# ESP32-P4 register map
Vendor: ESPRESSIF SYSTEMS (SHANGHAI) CO., LTD.; Series: ESP32 P-Series; File version: 3
CPU: RV32IMAFC r0p0, little endian, no MPU, FPU, 0 interrupt priority bits
Address unit: 32 bits
Registers are 32-bit, read-write, reset 0x0 unless marked. A register's access mark holds for its fields unless they carry their own. Offsets are from the block's base; [hi:lo] are bit positions; lines under a group give offsets from that group; {n}, {i} and the like mark numbered series; <NAME> marks a mode.

## H264 — H264 Encoder (Core)
Base 0x50084000
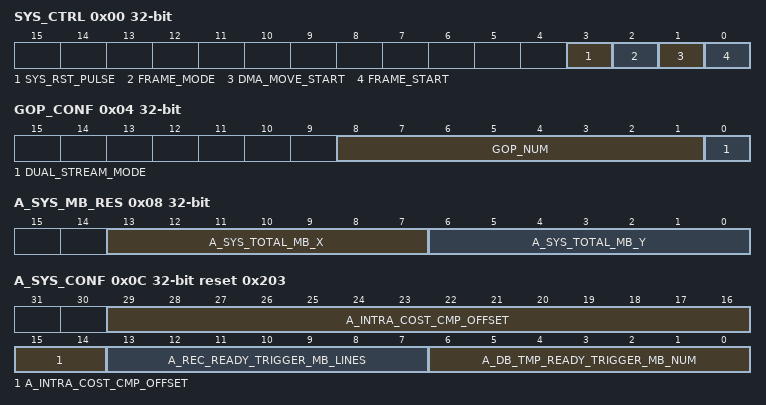
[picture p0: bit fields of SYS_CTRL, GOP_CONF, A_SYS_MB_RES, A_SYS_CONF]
0x00 SYS_CTRL access per field — H264 system level control register.
  [3] SYS_RST_PULSE wo — Configures whether or not to reset H264 ip.\\0: Invalid. No effect\\1: Reset H264 ip
  [2] FRAME_MODE rw — Configures H264 running mode. When field H264_DUAL_STREAM_MODE is set to 1, this field must be set to 1 too.\\0: GOP mode. Before every GOP first frame start, need reconfig reference frame DMA\\1: Frame mode. Before every frame start, need reconfig reference frame DMA
  [1] DMA_MOVE_START wo — Configures whether or not to start moving reference data from external mem.\\0: Invalid. No effect\\1: H264 start moving two MB lines of reference frame from external mem to internal mem
  [0] FRAME_START wo — Configures whether or not to start encoding one frame.\\0: Invalid. No effect\\1: Start encoding one frame
0x04 GOP_CONF — GOP related configuration register.
  [8:1] GOP_NUM — Configures the frame number of one GOP.\\0: The frame number of one GOP is infinite\\Others: Actual frame number of one GOP
  [0] DUAL_STREAM_MODE — Configures whether or not to enable dual stream mode. When this field is set to 1, H264_FRAME_MODE field must be set to 1 too.\\0: Normal mode\\1: Dual stream mode
0x08 A_SYS_MB_RES — Video A horizontal and vertical MB resolution register.
  [13:7] A_SYS_TOTAL_MB_X — Configures video A horizontal MB resolution.
  [6:0] A_SYS_TOTAL_MB_Y — Configures video A vertical MB resolution.
0x0C A_SYS_CONF reset 0x203 — Video A system level configuration register.
  [29:14] A_INTRA_COST_CMP_OFFSET — Configures video A intra cost offset when I MB compared with P MB.
  [13:7] A_REC_READY_TRIGGER_MB_LINES — Configures when to trigger video A H264_REC_READY_INT. When the MB line number of generated reconstruct pixel is greater than this filed, trigger H264_REC_READY_INT. Min is 4.
  [6:0] A_DB_TMP_READY_TRIGGER_MB_NUM — Configures when to trigger video A H264_DB_TMP_READY_INT. When the (MB number of written db temp+1) is greater than this filed in first MB line, trigger H264_DB_TMP_READY_INT. Min is 3.
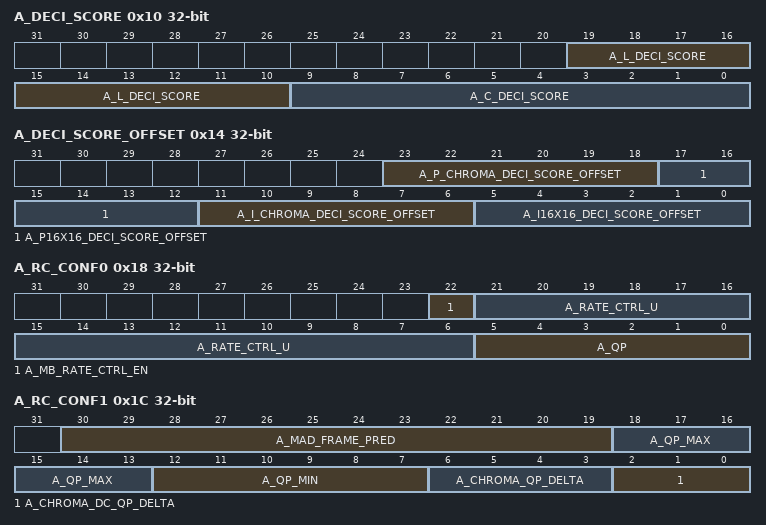
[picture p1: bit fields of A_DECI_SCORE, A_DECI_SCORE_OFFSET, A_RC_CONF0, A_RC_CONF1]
0x10 A_DECI_SCORE — Video A luma and chroma MB decimate score Register.
  [19:10] A_L_DECI_SCORE — Configures video A luma MB decimate score. When luma score is smaller than it, luma decimate will be enable.
  [9:0] A_C_DECI_SCORE — Configures video A chroma MB decimate score. When chroma score is smaller than it, chroma decimate will be enable.
0x14 A_DECI_SCORE_OFFSET — Video A luma and chroma MB decimate score offset Register.
  [23:18] A_P_CHROMA_DECI_SCORE_OFFSET — Configures video A p chroma MB decimate score offset. This offset will be added to p chroma MB score.
  [17:12] A_P16X16_DECI_SCORE_OFFSET — Configures video A p16x16 MB decimate score offset. This offset will be added to p16x16 MB score.
  [11:6] A_I_CHROMA_DECI_SCORE_OFFSET — Configures video A I chroma MB decimate score offset. This offset will be added to I chroma MB score.
  [5:0] A_I16X16_DECI_SCORE_OFFSET — Configures video A i16x16 MB decimate score offset. This offset will be added to i16x16 MB score.
0x18 A_RC_CONF0 — Video A rate control configuration register0.
  [22] A_MB_RATE_CTRL_EN — Configures video A whether or not to open macro block rate ctrl.\\1:Open the macro block rate ctrl\\1:Close the macro block rate ctrl.
  [21:6] A_RATE_CTRL_U — Configures video A parameter U value. U = int((float) u << 8).
  [5:0] A_QP — Configures video A frame level initial luma QP value.
0x1C A_RC_CONF1 — Video A rate control configuration register1.
  [30:19] A_MAD_FRAME_PRED — Configures vdieo A frame level predicted MB MAD value.
  [18:13] A_QP_MAX — Configures video A allowed luma QP max value.
  [12:7] A_QP_MIN — Configures video A allowed luma QP min value.
  [6:3] A_CHROMA_QP_DELTA — Configures video A chroma QP offset based on luma QP. Chroma QP(before map) = Luma QP + reg_chroma_qp_delta.
  [2:0] A_CHROMA_DC_QP_DELTA — Configures video A chroma DC QP offset based on Chroma QP. Chroma DC QP = Chroma QP(after map) + reg_chroma_dc_qp_delta.
0x20 A_DB_BYPASS — Video A Deblocking bypass register
  [0] A_BYPASS_DB_FILTER — Configures whether or not to bypass video A deblcoking filter. \\0: Open the deblock filter\\1: Close the deblock filter
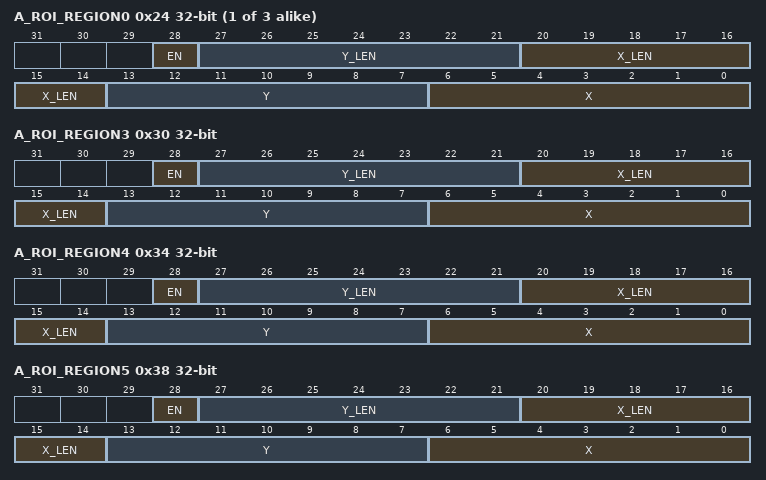
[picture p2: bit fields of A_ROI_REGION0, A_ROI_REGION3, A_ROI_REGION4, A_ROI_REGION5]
{0x24+4i} A_ROI_REGION{i} (i=0..2) — Video A H264 ROI region{i} range configure register.
  [28] EN — Configures whether or not to open Video A ROI of region {i} .\\0:Close ROI\\1:Open ROI.
  [27:21] Y_LEN — Configures the number of macroblocks in vertical direction of the region {i} in Video A.
  [20:14] X_LEN — Configures the number of macroblocks in horizontal direction of the region {i} in Video A.
  [13:7] Y — Configures the vertical start macroblocks of region {i} in Video A.
  [6:0] X — Configures the horizontal start macroblocks of region {i} in Video A.
0x30 A_ROI_REGION3 — Video A H264 ROI region3 range configure register.
  [28] EN — Configures whether or not to open Video A ROI of region 3 .\\0:Close ROI\\1:Open ROI.
  [27:21] Y_LEN — Configures the number of macroblocks in vertical direction of the region 3 in video A.
  [20:14] X_LEN — Configures the number of macroblocks in horizontal direction of the region 3 in video A.
  [13:7] Y — Configures the vertical start macroblocks of region 3 in Video A.
  [6:0] X — Configures the horizontal start macroblocks of region 3 in Video A.
0x34 A_ROI_REGION4 — Video A H264 ROI region4 range configure register.
  [28] EN — Configures whether or not to open Video A ROI of region 4 .\\0:Close ROI\\1:Open ROI.
  [27:21] Y_LEN — Configures the number of macroblocks in vertical direction of the region 4 in video A.
  [20:14] X_LEN — Configures the number of macroblocks in horizontal direction of the region 4 in video A.
  [13:7] Y — Configures the vertical start macroblocks of region 4 in Video A.
  [6:0] X — Configures the horizontal start macroblocks of region 4 in Video A.
0x38 A_ROI_REGION5 — Video A H264 ROI region5 range configure register.
  [28] EN — Configures whether or not to open Video A ROI of region 5 .\\0:Close ROI\\1:Open ROI.
  [27:21] Y_LEN — Configures the number of macroblocks in vertical direction of the region 5 in video A.
  [20:14] X_LEN — Configures the number of macroblocks in horizontal direction of the region 5 video A.
  [13:7] Y — Configures the vertical start macroblocks of region 5 video A.
  [6:0] X — Configures the horizontial start macroblocks of region 5 video A.
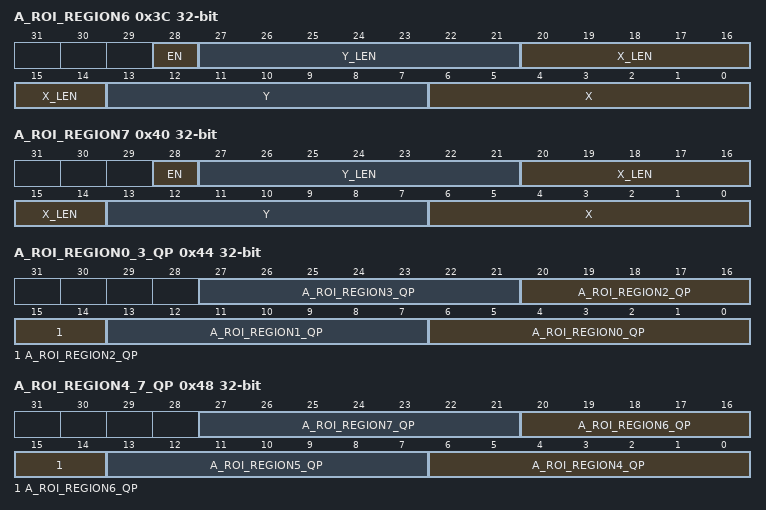
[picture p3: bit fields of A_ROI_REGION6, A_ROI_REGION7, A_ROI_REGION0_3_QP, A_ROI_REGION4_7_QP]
0x3C A_ROI_REGION6 — Video A H264 ROI region6 range configure register.
  [28] EN — Configures whether or not to open Video A ROI of region 6 .\\0:Close ROI\\1:Open ROI.
  [27:21] Y_LEN — Configures the number of macroblocks in vertical direction of the region 6 in video A.
  [20:14] X_LEN — Configures the number of macroblocks in horizontal direction of the region 6 in video A.
  [13:7] Y — Configures the vertical start macroblocks of region 6 in video A.
  [6:0] X — Configures the horizontial start macroblocks of region 6 video A.
0x40 A_ROI_REGION7 — Video A H264 ROI region7 range configure register.
  [28] EN — Configures whether or not to open Video A ROI of region 7 .\\0:Close ROI\\1:Open ROI.
  [27:21] Y_LEN — Configures the number of macroblocks in vertical direction of the region 7 in video A.
  [20:14] X_LEN — Configures the number of macroblocks in horizontal direction of the region 7 in video A.
  [13:7] Y — Configures the vertical start macroblocks of region 7 in video A.
  [6:0] X — Configures the horizontal start macroblocks of region 7 in video A.
0x44 A_ROI_REGION0_3_QP — Video A H264 ROI region0, region1,region2,region3 QP register.
  [7n+6:7n] A_ROI_REGION{n}_QP (n=0..3) — Configure H264 ROI region{n} qp in video A,fixed qp or delta qp.
0x48 A_ROI_REGION4_7_QP — Video A H264 ROI region4, region5,region6,region7 QP register.
  [7n-22:7n-28] A_ROI_REGION{n}_QP (n=4..7) — Configure H264 ROI region{n} qp in video A,fixed qp or delta qp.
0x4C A_NO_ROI_REGION_QP_OFFSET — Video A H264 no roi region QP register.
  [6:0] A_NO_ROI_REGION_QP — Configure H264 no region qp in video A, delta qp.
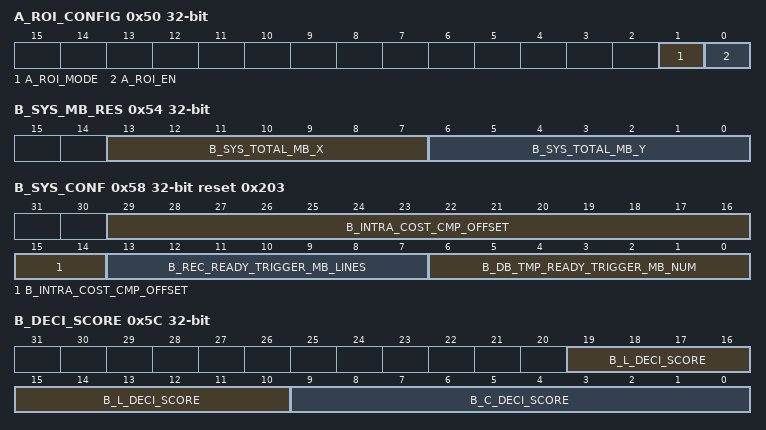
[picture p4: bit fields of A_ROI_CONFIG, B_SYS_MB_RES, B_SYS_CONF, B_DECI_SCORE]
0x50 A_ROI_CONFIG — Video A H264 ROI configure register.
  [1] A_ROI_MODE — Configure the mode of ROI in video A.\\0:fixed qp\\1:delta qp.
  [0] A_ROI_EN — Configure whether or not to enable ROI in video A.\\0:not enable ROI\\1:enable ROI.
0x54 B_SYS_MB_RES — Video B horizontal and vertical MB resolution register.
  [13:7] B_SYS_TOTAL_MB_X — Configures video B horizontal MB resolution.
  [6:0] B_SYS_TOTAL_MB_Y — Configures video B vertical MB resolution.
0x58 B_SYS_CONF reset 0x203 — Video B system level configuration register.
  [29:14] B_INTRA_COST_CMP_OFFSET — Configures video B intra cost offset when I MB compared with P MB.
  [13:7] B_REC_READY_TRIGGER_MB_LINES — Configures when to trigger video B H264_REC_READY_INT. When the MB line number of generated reconstruct pixel is greater than this filed, trigger H264_REC_READY_INT. Min is 4.
  [6:0] B_DB_TMP_READY_TRIGGER_MB_NUM — Configures when to trigger video B H264_DB_TMP_READY_INT. When the (MB number of written db temp+1) is greater than this filed in first MB line, trigger H264_DB_TMP_READY_INT. Min is 3.
0x5C B_DECI_SCORE — Video B luma and chroma MB decimate score Register.
  [19:10] B_L_DECI_SCORE — Configures video B luma MB decimate score. When luma score is smaller than it, luma decimate will be enable.
  [9:0] B_C_DECI_SCORE — Configures video B chroma MB decimate score. When chroma score is smaller than it, chroma decimate will be enable.
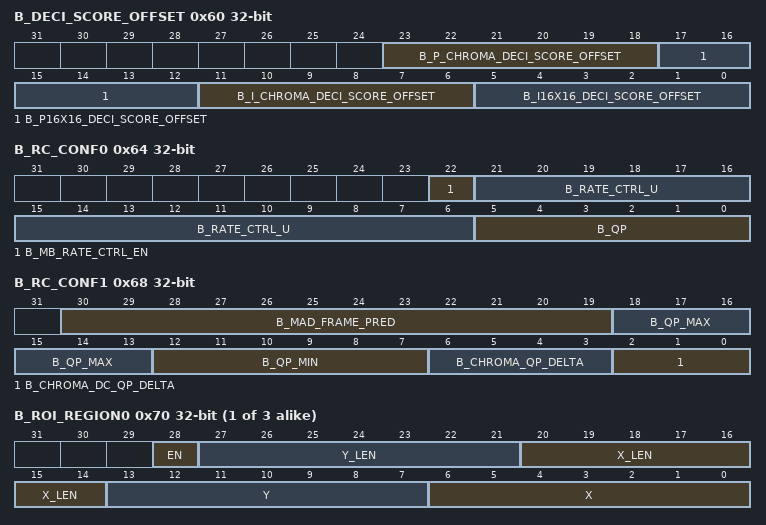
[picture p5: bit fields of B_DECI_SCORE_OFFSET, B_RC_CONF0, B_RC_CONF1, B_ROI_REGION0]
0x60 B_DECI_SCORE_OFFSET — Video B luma and chroma MB decimate score offset Register.
  [23:18] B_P_CHROMA_DECI_SCORE_OFFSET — Configures video B p chroma MB decimate score offset. This offset will be added to p chroma MB score.
  [17:12] B_P16X16_DECI_SCORE_OFFSET — Configures video B p16x16 MB decimate score offset. This offset will be added to p16x16 MB score.
  [11:6] B_I_CHROMA_DECI_SCORE_OFFSET — Configures video B I chroma MB decimate score offset. This offset will be added to I chroma MB score.
  [5:0] B_I16X16_DECI_SCORE_OFFSET — Configures video B i16x16 MB decimate score offset. This offset will be added to i16x16 MB score.
0x64 B_RC_CONF0 — Video B rate control configuration register0.
  [22] B_MB_RATE_CTRL_EN — Configures video A whether or not to open macro block rate ctrl.\\1:Open the macro block rate ctrl\\1:Close the macro block rate ctrl.
  [21:6] B_RATE_CTRL_U — Configures video B parameter U value. U = int((float) u << 8).
  [5:0] B_QP — Configures video B frame level initial luma QP value.
0x68 B_RC_CONF1 — Video B rate control configuration register1.
  [30:19] B_MAD_FRAME_PRED — Configures vdieo B frame level predicted MB MAD value.
  [18:13] B_QP_MAX — Configures video B allowed luma QP max value.
  [12:7] B_QP_MIN — Configures video B allowed luma QP min value.
  [6:3] B_CHROMA_QP_DELTA — Configures video B chroma QP offset based on luma QP. Chroma QP(before map) = Luma QP + reg_chroma_qp_delta.
  [2:0] B_CHROMA_DC_QP_DELTA — Configures video B chroma DC QP offset based on Chroma QP. Chroma DC QP = Chroma QP(after map) + reg_chroma_dc_qp_delta.
0x6C B_DB_BYPASS — Video B Deblocking bypass register
  [0] B_BYPASS_DB_FILTER — Configures whether or not to bypass video B deblcoking filter. \\0: Open the deblock filter\\1: Close the deblock filter
{0x70+4i} B_ROI_REGION{i} (i=0..2) — Video B H264 ROI region{i} range configure register.
  [28] EN — Configures whether or not to open Video B ROI of region {i} .\\0:Close ROI\\1:Open ROI.
  [27:21] Y_LEN — Configures the number of macroblocks in vertical direction of the region {i} in Video B.
  [20:14] X_LEN — Configures the number of macroblocks in horizontal direction of the region {i} in Video B.
  [13:7] Y — Configures the vertical start macroblocks of region {i} in Video B.
  [6:0] X — Configures the horizontal start macroblocks of region {i} in Video B.
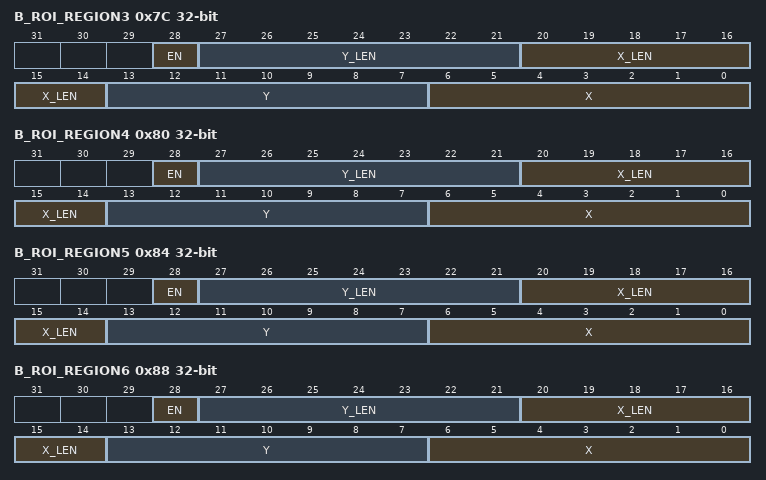
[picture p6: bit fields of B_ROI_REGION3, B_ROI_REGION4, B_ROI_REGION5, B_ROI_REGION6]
0x7C B_ROI_REGION3 — Video B H264 ROI region3 range configure register.
  [28] EN — Configures whether or not to open Video B ROI of region 3 .\\0:Close ROI\\1:Open ROI.
  [27:21] Y_LEN — Configures the number of macroblocks in vertical direction of the region 3 in video B.
  [20:14] X_LEN — Configures the number of macroblocks in horizontal direction of the region 3 in video B.
  [13:7] Y — Configures the vertical start macroblocks of region 3 in Video B.
  [6:0] X — Configures the horizontal start macroblocks of region 3 in Video B.
0x80 B_ROI_REGION4 — Video B H264 ROI region4 range configure register.
  [28] EN — Configures whether or not to open Video B ROI of region 4 .\\0:Close ROI\\1:Open ROI.
  [27:21] Y_LEN — Configures the number of macroblocks in vertical direction of the region 4 in video B.
  [20:14] X_LEN — Configures the number of macroblocks in horizontal direction of the region 4 in video B.
  [13:7] Y — Configures the vertical start macroblocks of region 4 in Video B.
  [6:0] X — Configures the horizontal start macroblocks of region 4 in Video B.
0x84 B_ROI_REGION5 — Video B H264 ROI region5 range configure register.
  [28] EN — Configures whether or not to open Video B ROI of region 5 .\\0:Close ROI\\1:Open ROI.
  [27:21] Y_LEN — Configures the number of macroblocks in vertical direction of the region 5 in video B.
  [20:14] X_LEN — Configures the number of macroblocks in horizontal direction of the region 5 video B.
  [13:7] Y — Configures the vertical start macroblocks of region 5 video B.
  [6:0] X — Configures the horizontial start macroblocks of region 5 video B.
0x88 B_ROI_REGION6 — Video B H264 ROI region6 range configure register.
  [28] EN — Configures whether or not to open Video B ROI of region 6 .\\0:Close ROI\\1:Open ROI.
  [27:21] Y_LEN — Configures the number of macroblocks in vertical direction of the region 6 in video B.
  [20:14] X_LEN — Configures the number of macroblocks in horizontal direction of the region 6 in video B.
  [13:7] Y — Configures the vertical start macroblocks of region 6 in video B.
  [6:0] X — Configures the horizontial start macroblocks of region 6 video B.
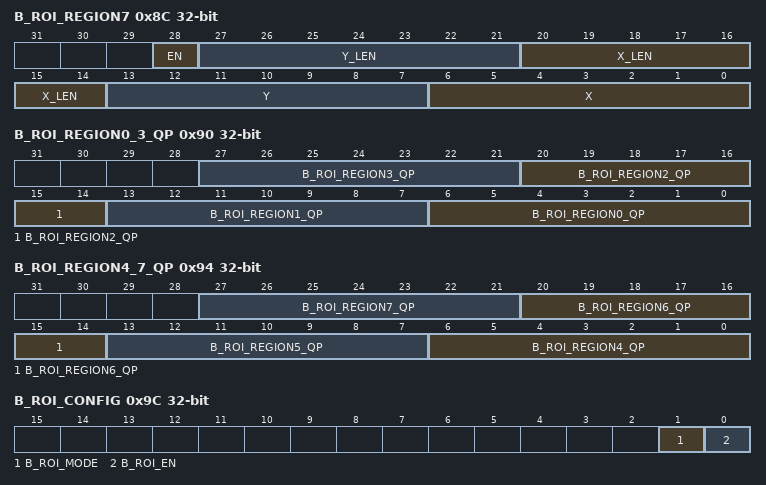
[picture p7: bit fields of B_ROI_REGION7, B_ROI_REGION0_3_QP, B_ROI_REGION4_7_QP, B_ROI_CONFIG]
0x8C B_ROI_REGION7 — Video B H264 ROI region7 range configure register.
  [28] EN — Configures whether or not to open Video B ROI of region 7 .\\0:Close ROI\\1:Open ROI.
  [27:21] Y_LEN — Configures the number of macroblocks in vertical direction of the region 7 in video B.
  [20:14] X_LEN — Configures the number of macroblocks in horizontal direction of the region 7 in video B.
  [13:7] Y — Configures the vertical start macroblocks of region 7 in video B.
  [6:0] X — Configures the horizontal start macroblocks of region 7 in video B.
0x90 B_ROI_REGION0_3_QP — Video B H264 ROI region0, region1,region2,region3 QP register.
  [7n+6:7n] B_ROI_REGION{n}_QP (n=0..3) — Configure H264 ROI region{n} qp in video B,fixed qp or delta qp.
0x94 B_ROI_REGION4_7_QP — Video B H264 ROI region4, region5,region6,region7 QP register.
  [7n-22:7n-28] B_ROI_REGION{n}_QP (n=4..7) — Configure H264 ROI region{n} qp in video B,fixed qp or delta qp.
0x98 B_NO_ROI_REGION_QP_OFFSET — Video B H264 no roi region QP register.
  [6:0] B_NO_ROI_REGION_QP — Configure H264 no region qp in video B, delta qp.
0x9C B_ROI_CONFIG — Video B H264 ROI configure register.
  [1] B_ROI_MODE — Configure the mode of ROI in video B.\\0:fixed qp\\1:delta qp.
  [0] B_ROI_EN — Configure whether or not to enable ROI in video B.\\0:not enable ROI\\1:enable ROI.
0xA0 RC_STATUS0 ro — Rate control status register0.
  [20:0] FRAME_MAD_SUM — Represents all MB actual MAD sum value of one frame.
0xA4 RC_STATUS1 ro — Rate control status register1.
  [26:0] FRAME_ENC_BITS — Represents all MB actual encoding bits sum value of one frame.
0xA8 RC_STATUS2 ro — Rate control status register2.
  [18:0] FRAME_QP_SUM — Represents all MB actual luma QP sum value of one frame.
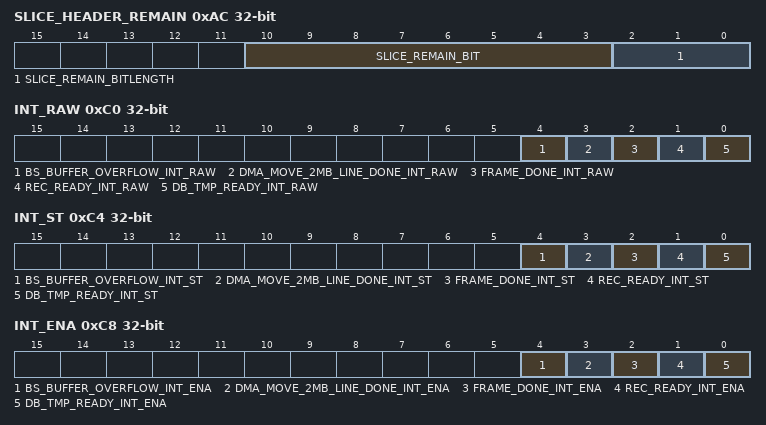
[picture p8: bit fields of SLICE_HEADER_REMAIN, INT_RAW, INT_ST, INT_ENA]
0xAC SLICE_HEADER_REMAIN — Frame Slice Header remain bit register.
  [10:3] SLICE_REMAIN_BIT — Configures Slice Header remain bit
  [2:0] SLICE_REMAIN_BITLENGTH — Configures Slice Header remain bit number
0xB0 SLICE_HEADER_BYTE_LENGTH — Frame Slice Header byte length register.
  [3:0] SLICE_BYTE_LENGTH — Configures Slice Header byte number
0xB4 BS_THRESHOLD reset 0x30 — Bitstream buffer overflow threshold register
  [6:0] BS_BUFFER_THRESHOLD — Configures bitstream buffer overflow threshold. This value should be bigger than the encode bytes of one 4x4 submb.
0xB8 SLICE_HEADER_BYTE0 — Frame Slice Header byte low 32 bit register.
  [31:0] SLICE_BYTE_LSB — Configures Slice Header low 32 bit
0xBC SLICE_HEADER_BYTE1 — Frame Slice Header byte high 32 bit register.
  [31:0] SLICE_BYTE_MSB — Configures Slice Header high 32 bit
0xC0 INT_RAW — Interrupt raw status register
  [4] BS_BUFFER_OVERFLOW_INT_RAW — Raw status bit: The raw interrupt status of H264_BS_BUFFER_OVERFLOW_INT. Triggered when H264 bit stream buffer overflow.
  [3] DMA_MOVE_2MB_LINE_DONE_INT_RAW — Raw status bit: The raw interrupt status of H264_DMA_MOVE_2MB_LINE_DONE_INT. Triggered when H264 move two MB lines of reference frame from external mem to internal mem done.
  [2] FRAME_DONE_INT_RAW — Raw status bit: The raw interrupt status of H264_FRAME_DONE_INT. Triggered when H264 encoding one frame done.
  [1] REC_READY_INT_RAW — Raw status bit: The raw interrupt status of H264_REC_READY_INT. Triggered when H264 encoding enough reconstruct pixel.
  [0] DB_TMP_READY_INT_RAW — Raw status bit: The raw interrupt status of H264_DB_TMP_READY_INT. Triggered when H264 written enough db tmp pixel.
0xC4 INT_ST ro — Interrupt masked status register
  [4] BS_BUFFER_OVERFLOW_INT_ST — Masked status bit: The masked interrupt status of H264_BS_BUFFER_OVERFLOW_INT. Valid only when the H264_BS_BUFFER_OVERFLOW_INT_ENA is set to 1.
  [3] DMA_MOVE_2MB_LINE_DONE_INT_ST — Masked status bit: The masked interrupt status of H264_DMA_MOVE_2MB_LINE_DONE_INT. Valid only when the H264_DMA_MOVE_2MB_LINE_DONE_INT_ENA is set to 1.
  [2] FRAME_DONE_INT_ST — Masked status bit: The masked interrupt status of H264_FRAME_DONE_INT. Valid only when the H264_FRAME_DONE_INT_ENA is set to 1.
  [1] REC_READY_INT_ST — Masked status bit: The masked interrupt status of H264_REC_READY_INT. Valid only when the H264_REC_READY_INT_ENA is set to 1.
  [0] DB_TMP_READY_INT_ST — Masked status bit: The masked interrupt status of H264_DB_TMP_READY_INT. Valid only when the H264_DB_TMP_READY_INT_ENA is set to 1.
0xC8 INT_ENA — Interrupt enable register
  [4] BS_BUFFER_OVERFLOW_INT_ENA — Enable bit: Write 1 to enable H264_BS_BUFFER_OVERFLOW_INT.
  [3] DMA_MOVE_2MB_LINE_DONE_INT_ENA — Enable bit: Write 1 to enable H264_DMA_MOVE_2MB_LINE_DONE_INT.
  [2] FRAME_DONE_INT_ENA — Enable bit: Write 1 to enable H264_FRAME_DONE_INT.
  [1] REC_READY_INT_ENA — Enable bit: Write 1 to enable H264_REC_READY_INT.
  [0] DB_TMP_READY_INT_ENA — Enable bit: Write 1 to enable H264_DB_TMP_READY_INT.
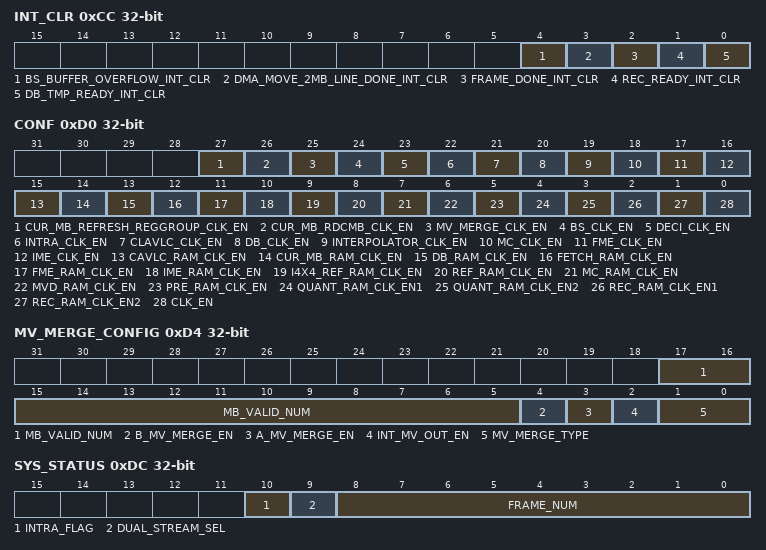
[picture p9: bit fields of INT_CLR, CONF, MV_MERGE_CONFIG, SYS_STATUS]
0xCC INT_CLR wo — Interrupt clear register
  [4] BS_BUFFER_OVERFLOW_INT_CLR — Clear bit: Write 1 to clear H264_BS_BUFFER_OVERFLOW_INT.
  [3] DMA_MOVE_2MB_LINE_DONE_INT_CLR — Clear bit: Write 1 to clear H264_DMA_MOVE_2MB_LINE_DONE_INT.
  [2] FRAME_DONE_INT_CLR — Clear bit: Write 1 to clear H264_FRAME_DONE_INT.
  [1] REC_READY_INT_CLR — Clear bit: Write 1 to clear H264_REC_READY_INT.
  [0] DB_TMP_READY_INT_CLR — Clear bit: Write 1 to clear H264_DB_TMP_READY_INT.
0xD0 CONF — General configuration register.
  [27] CUR_MB_REFRESH_REGGROUP_CLK_EN — Configures whether or not to open the clock gate for cur_mb refresh register group.\\0: Open the clock gate only when cur_mb refresh register group work\\1: Force open the clock gate for cur_mb refresh register group
  [26] CUR_MB_RDCMB_CLK_EN — Configures whether or not to open the clock gate for cur_mb read macroblock.\\0: Open the clock gate only when cur_mb read macroblock work\\1: Force open the clock gate for cur_mb read macroblock
  [25] MV_MERGE_CLK_EN — Configures whether or not to open the clock gate for mv merge.\\0: Open the clock gate only when mv merge work\\1: Force open the clock gate for mv merge
  [24] BS_CLK_EN — Configures whether or not to open the clock gate for bs buffer.\\0: Open the clock gate only when bs buffer work\\1: Force open the clock gate for bs buffer
  [23] DECI_CLK_EN — Configures whether or not to open the clock gate for decimate.\\0: Open the clock gate only when decimate work\\1: Force open the clock gate for decimate
  [22] INTRA_CLK_EN — Configures whether or not to open the clock gate for intra.\\0: Open the clock gate only when intra work\\1: Force open the clock gate for intra
  [21] CLAVLC_CLK_EN — Configures whether or not to open the clock gate for cavlc.\\0: Open the clock gate only when cavlc work\\1: Force open the clock gate for cavlc
  [20] DB_CLK_EN — Configures whether or not to open the clock gate for deblocking filter.\\0: Open the clock gate only when deblocking filter work\\1: Force open the clock gate for deblocking filter
  [19] INTERPOLATOR_CLK_EN — Configures whether or not to open the clock gate for interpolator.\\0: Open the clock gate only when interpolator work\\1: Force open the clock gate for interpolator
  [18] MC_CLK_EN — Configures whether or not to open the clock gate for mc.\\0: Open the clock gate only when mc work\\1: Force open the clock gate for mc
  [17] FME_CLK_EN — Configures whether or not to open the clock gate for fme.\\0: Open the clock gate only when fme work\\1: Force open the clock gate for fme
  [16] IME_CLK_EN — Configures whether or not to open the clock gate for ime.\\0: Open the clock gate only when ime work\\1: Force open the clock gate for ime
  [15] CAVLC_RAM_CLK_EN — Configures whether or not to open the clock gate for cavlc ram.\\0: Open the clock gate only when application writes or reads cavlc ram\\1: Force open the clock gate for cavlc ram
  [14] CUR_MB_RAM_CLK_EN — Configures whether or not to open the clock gate for cur_mb ram.\\0: Open the clock gate only when application writes or reads cur_mb ram\\1: Force open the clock gate for cur_mb ram
  [13] DB_RAM_CLK_EN — Configures whether or not to open the clock gate for db ram.\\0: Open the clock gate only when application writes or reads db ram\\1: Force open the clock gate for db ram
  [12] FETCH_RAM_CLK_EN — Configures whether or not to open the clock gate for fetch ram.\\0: Open the clock gate only when application writes or reads fetch ram\\1: Force open the clock gate for fetch ram
  [11] FME_RAM_CLK_EN — Configures whether or not to open the clock gate for fme ram.\\0: Open the clock gate only when application writes or readsfme ram\\1: Force open the clock gate for fme ram
  [10] IME_RAM_CLK_EN — Configures whether or not to open the clock gate for ime ram.\\0: Open the clock gate only when application writes or reads ime ram\\1: Force open the clock gate for ime ram
  [9] I4X4_REF_RAM_CLK_EN — Configures whether or not to open the clock gate for i4x4_mode ram.\\0: Open the clock gate only when application writes or reads i4x4_mode ram\\1: Force open the clock gate for i4x4_mode ram
  [8] REF_RAM_CLK_EN — Configures whether or not to open the clock gate for ref ram.\\0: Open the clock gate only when application writes or reads ref ram\\1: Force open the clock gate for ref ram
  [7] MC_RAM_CLK_EN — Configures whether or not to open the clock gate for mc ram.\\0: Open the clock gate only when application writes or reads mc ram\\1: Force open the clock gate for mc ram
  [6] MVD_RAM_CLK_EN — Configures whether or not to open the clock gate for mvd ram.\\0: Open the clock gate only when application writes or reads mvd ram\\1: Force open the clock gate for mvd ram
  [5] PRE_RAM_CLK_EN — Configures whether or not to open the clock gate for pre ram.\\0: Open the clock gate only when application writes or reads pre ram\\1: Force open the clock gate for pre ram
  [4] QUANT_RAM_CLK_EN1 — Configures whether or not to open the clock gate for quant ram1.\\0: Open the clock gate only when application writes or reads quant ram1\\1: Force open the clock gate for quant ram1
  [3] QUANT_RAM_CLK_EN2 — Configures whether or not to open the clock gate for quant ram2.\\0: Open the clock gate only when application writes or reads quant ram2\\1: Force open the clock gate for quant ram2
  [2] REC_RAM_CLK_EN1 — Configures whether or not to open the clock gate for rec ram1.\\0: Open the clock gate only when application writes or reads rec ram1\\1: Force open the clock gate for rec ram1
  [1] REC_RAM_CLK_EN2 — Configures whether or not to open the clock gate for rec ram2.\\0: Open the clock gate only when application writes or reads rec ram2\\1: Force open the clock gate for rec ram2
  [0] CLK_EN — Configures whether or not to open register clock gate.\\0: Open the clock gate only when application writes registers\\1: Force open the clock gate for register
0xD4 MV_MERGE_CONFIG access per field — Mv merge configuration register.
  [17:5] MB_VALID_NUM ro — Represents the valid mb number of mv merge output.
  [4] B_MV_MERGE_EN rw — Configure whether or not to enable video B mv merge.\\0: disable\\1: enable.
  [3] A_MV_MERGE_EN rw — Configure whether or not to enable video A mv merge.\\0: disable\\1: enable.
  [2] INT_MV_OUT_EN rw — Configure mv merge output integer part not zero mv or all part not zero mv.\\0: output all part not zero mv\\1: output integer part not zero mv.
  [1:0] MV_MERGE_TYPE rw — Configure mv merge type.\\0: merge p16x16 mv\\1: merge min mv\\2: merge max mv\\3: not valid.
0xD8 DEBUG_DMA_SEL — Debug H264 DMA select register
  [7:0] DBG_DMA_SEL — Every bit represents a dma in h264
0xDC SYS_STATUS ro — System status register.
  [10] INTRA_FLAG — Represents the type of current encoding frame.\\0: P frame\\1: I frame.
  [9] DUAL_STREAM_SEL — Represents which register group is used for cur frame.\\0: Register group A is used\\1: Register group B is used.
  [8:0] FRAME_NUM — Represents current frame number.
0xE0 FRAME_CODE_LENGTH ro — Frame code byte length register.
  [23:0] FRAME_CODE_LENGTH — Represents current frame code byte length.
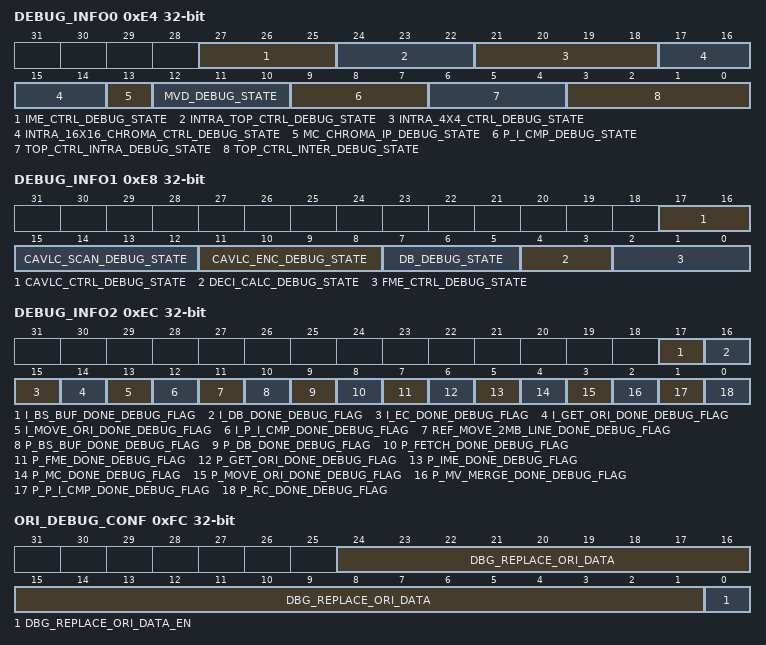
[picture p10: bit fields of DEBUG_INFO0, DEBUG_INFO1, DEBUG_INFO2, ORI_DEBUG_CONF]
0xE4 DEBUG_INFO0 ro — Debug information register0.
  [27:25] IME_CTRL_DEBUG_STATE — Represents ime_ctrl module FSM info.
  [24:22] INTRA_TOP_CTRL_DEBUG_STATE — Represents intra_top_ctrl module FSM info.
  [21:18] INTRA_4X4_CTRL_DEBUG_STATE — Represents intra_4x4_ctrl module FSM info.
  [17:14] INTRA_16X16_CHROMA_CTRL_DEBUG_STATE — Represents intra_16x16_chroma_ctrl module FSM info.
  [13] MC_CHROMA_IP_DEBUG_STATE — Represents mc_chroma_ip module FSM info.
  [12:10] MVD_DEBUG_STATE — Represents mvd module FSM info.
  [9:7] P_I_CMP_DEBUG_STATE — Represents p_i_cmp module FSM info.
  [6:4] TOP_CTRL_INTRA_DEBUG_STATE — Represents top_ctrl_intra module FSM info.
  [3:0] TOP_CTRL_INTER_DEBUG_STATE — Represents top_ctrl_inter module FSM info.
0xE8 DEBUG_INFO1 ro — Debug information register1.
  [17:16] CAVLC_CTRL_DEBUG_STATE — Represents cavlc module ctrl FSM info.
  [15:12] CAVLC_SCAN_DEBUG_STATE — Represents cavlc module scan FSM info.
  [11:8] CAVLC_ENC_DEBUG_STATE — Represents cavlc module enc FSM info.
  [7:5] DB_DEBUG_STATE — Represents db module FSM info.
  [4:3] DECI_CALC_DEBUG_STATE — Represents deci_calc module's FSM info. DEV use only.
  [2:0] FME_CTRL_DEBUG_STATE — Represents fme_ctrl module FSM info.
0xEC DEBUG_INFO2 ro — Debug information register2.
  [17] I_BS_BUF_DONE_DEBUG_FLAG — Represents I bitstream buffer done status.\\0: not done\\1: done.
  [16] I_DB_DONE_DEBUG_FLAG — Represents I deblocking done status.\\0: not done\\1: done.
  [15] I_EC_DONE_DEBUG_FLAG — Represents I encoder done status.\\0: not done\\1: done.
  [14] I_GET_ORI_DONE_DEBUG_FLAG — Represents I get origin done status.\\0: not done\\1: done.
  [13] I_MOVE_ORI_DONE_DEBUG_FLAG — Represents I move origin done status.\\0: not done\\1: done.
  [12] I_P_I_CMP_DONE_DEBUG_FLAG — Represents I p_i_cmp done status.\\0: not done\\1: done.
  [11] REF_MOVE_2MB_LINE_DONE_DEBUG_FLAG — Represents dma move 2 ref mb line done status.\\0: not done\\1: done.
  [10] P_BS_BUF_DONE_DEBUG_FLAG — Represents p bitstream buffer done status.\\0: not done\\1: done.
  [9] P_DB_DONE_DEBUG_FLAG — Represents p deblocking done status.\\0: not done\\1: done.
  [8] P_FETCH_DONE_DEBUG_FLAG — Represents p fetch done status.\\0: not done\\1: done.
  [7] P_FME_DONE_DEBUG_FLAG — Represents p fme done status.\\0: not done\\1: done.
  [6] P_GET_ORI_DONE_DEBUG_FLAG — Represents p get origin done status.\\0: not done\\1: done.
  [5] P_IME_DONE_DEBUG_FLAG — Represents p ime done status.\\0: not done\\1: done.
  [4] P_MC_DONE_DEBUG_FLAG — Represents p mc done status.\\0: not done\\1: done.
  [3] P_MOVE_ORI_DONE_DEBUG_FLAG — Represents p move origin done status.\\0: not done\\1: done.
  [2] P_MV_MERGE_DONE_DEBUG_FLAG — Represents p mv merge done status.\\0: not done\\1: done.
  [1] P_P_I_CMP_DONE_DEBUG_FLAG — Represents p p_i_cmp done status.\\0: not done\\1: done.
  [0] P_RC_DONE_DEBUG_FLAG — Represents p rate ctrl done status.\\0: not done\\1: done.
0xF0 DATE reset 0x2412300 — Version control register
  [27:0] DATE — Configures the version.
0xF4 A_ORI_CONF reset 0x4 — Video A original picture configuration register.
  [2:0] A_ORI_COLOR_SPACE — Configures video A original picture color space.\\0: RGB888\\1: RGB565\\2: YUV444\\3: YUV422\\4: YUV420\\5: GRAY\\Others: Invalid
0xF8 B_ORI_CONF reset 0x4 — Video B original picture configuration register.
  [2:0] B_ORI_COLOR_SPACE — Configures video B original picture color space.\\0: RGB888\\1: RGB565\\2: YUV444\\3: YUV422\\4: YUV420\\5: GRAY\\Others: Invalid
0xFC ORI_DEBUG_CONF — Original picture debug configuration register.
  [24:1] DBG_REPLACE_ORI_DATA — Configures original picture pixels to be replaced. When the original picture color space is RGB, byte0~2 is BGR. When the original picture color space is YUV, byte0~2 is VUY. When the original picture color space is GRAY, byte0 is GRAY.
  [0] DBG_REPLACE_ORI_DATA_EN — Configures whether to replace original picture pixels.\\0: not replace\\1: replace
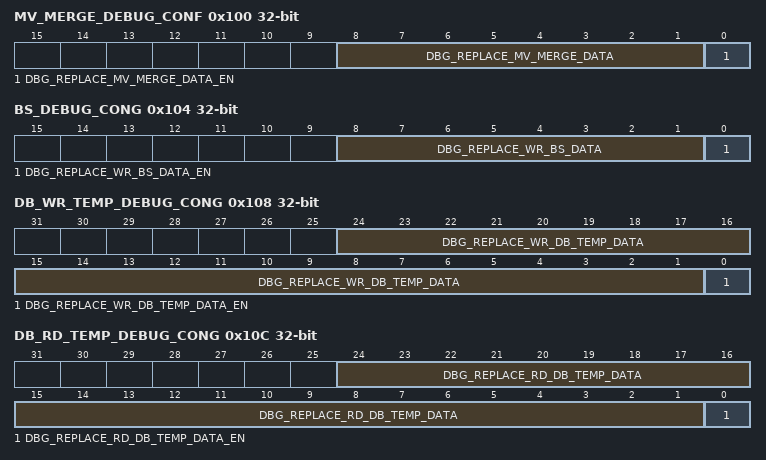
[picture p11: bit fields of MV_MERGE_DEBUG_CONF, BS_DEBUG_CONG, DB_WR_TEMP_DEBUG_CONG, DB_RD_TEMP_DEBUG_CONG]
0x100 MV_MERGE_DEBUG_CONF — Original picture debug configuration register.
  [8:1] DBG_REPLACE_MV_MERGE_DATA — Configures mv merge data to be replaced.
  [0] DBG_REPLACE_MV_MERGE_DATA_EN — Configures whether to replace mv merge data.\\0: not replace\\1: replace
0x104 BS_DEBUG_CONG — Encode bitstream debug configuration register
  [8:1] DBG_REPLACE_WR_BS_DATA — Configures bs data to be replaced
  [0] DBG_REPLACE_WR_BS_DATA_EN — Configures whether or not to replace bs data.\\0: not replace\\1: replace
0x108 DB_WR_TEMP_DEBUG_CONG — Deblocking filter write temp debug configuration register
  [24:1] DBG_REPLACE_WR_DB_TEMP_DATA — Configure deblocking filter write temp data to be replaced.byte0~2 is VUY
  [0] DBG_REPLACE_WR_DB_TEMP_DATA_EN — Configure deblocking fliter whether or not to replace write temp data.\\0: not replace\\1: replace
0x10C DB_RD_TEMP_DEBUG_CONG — Deblocking filter read temp debug configuration register
  [24:1] DBG_REPLACE_RD_DB_TEMP_DATA — Configure deblocking filter read temp data to be replaced.byte0~2 is VUY
  [0] DBG_REPLACE_RD_DB_TEMP_DATA_EN — Configure deblocking fliter whether or not to replace read temp data.\\0: not replace\\1: replace
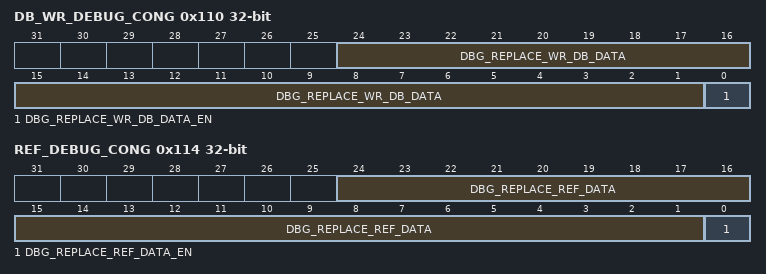
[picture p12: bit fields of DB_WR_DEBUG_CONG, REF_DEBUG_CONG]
0x110 DB_WR_DEBUG_CONG — Deblocking filter final data debug configuration register
  [24:1] DBG_REPLACE_WR_DB_DATA — Configure deblocking filter write data to be replaced.byte0~2 is VUY
  [0] DBG_REPLACE_WR_DB_DATA_EN — Configure deblocking fliter whether or not to replace write data.\\0: not replace\\1: replace
0x114 REF_DEBUG_CONG — Deblocking filter final data debug configuration register
  [24:1] DBG_REPLACE_REF_DATA — Configure reference picture pixels to be replaced.byte0~2 is VUY
  [0] DBG_REPLACE_REF_DATA_EN — Configure whether to replace reference picture pixels.\\0: not replace\\1: replace
